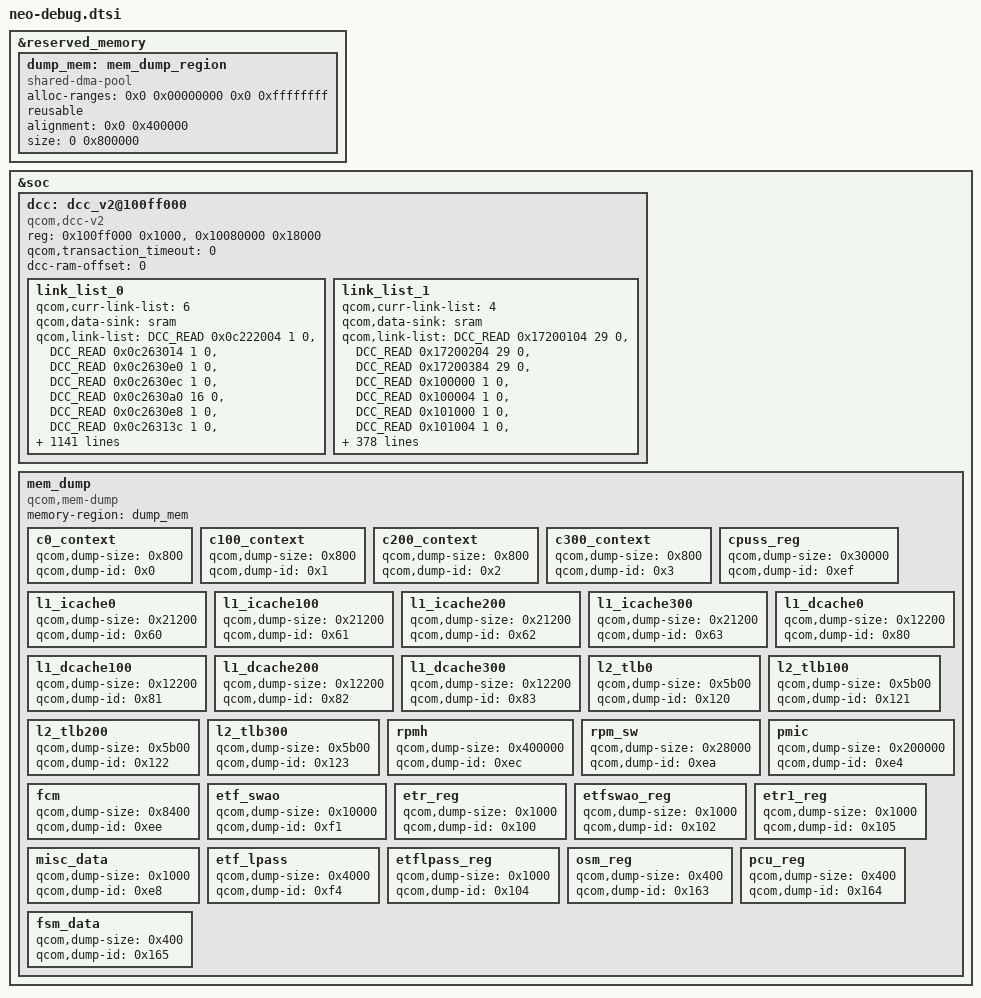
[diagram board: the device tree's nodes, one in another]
#include <dt-bindings/soc/qcom,dcc_v2.h>

&reserved_memory {
	#address-cells = <2>;
	#size-cells = <2>;
	ranges;

	dump_mem: mem_dump_region {
		compatible = "shared-dma-pool";
		alloc-ranges = <0x0 0x00000000 0x0 0xffffffff>;
		reusable;
		alignment = <0x0 0x400000>;
		size = <0 0x800000>;
	};
};

&soc {

	dcc: dcc_v2@100ff000 {
		compatible = "qcom,dcc-v2";
		reg = <0x100ff000 0x1000>,
		      <0x10080000 0x18000>;

		qcom,transaction_timeout = <0>;

		reg-names = "dcc-base", "dcc-ram-base";
		dcc-ram-offset = <0>;

		link_list_0 {
			qcom,curr-link-list = <6>;
			qcom,data-sink = "sram";
			qcom,link-list = <DCC_READ 0x0c222004 1 0>,
					<DCC_READ 0x0c263014 1 0>,
					<DCC_READ 0x0c2630e0 1 0>,
					<DCC_READ 0x0c2630ec 1 0>,
					<DCC_READ 0x0c2630a0 16 0>,
					<DCC_READ 0x0c2630e8 1 0>,
					<DCC_READ 0x0c26313c 1 0>,
					<DCC_READ 0x17b784a0 12 0>,
					<DCC_READ 0x17b78520 1 0>,
					<DCC_READ 0x17b78588 1 0>,
					<DCC_READ 0x17b78D90 8 0>,
					<DCC_READ 0x17b79010 6 0>,
					<DCC_READ 0x17b79090 6 0>,
					<DCC_READ 0x17b79a90 4 0>,
					<DCC_READ 0xec80010 1 0>,
					<DCC_READ 0xec81000 1 0>,
					<DCC_READ 0xec81010 16 0>,
					<DCC_READ 0xec81050 16 0>,
					<DCC_READ 0xec81090 16 0>,
					<DCC_READ 0xec810d0 16 0>,
					<DCC_READ 0x17800058 1 0>,
					<DCC_READ 0x17810058 1 0>,
					<DCC_READ 0x17820058 1 0>,
					<DCC_READ 0x17830058 1 0>,
					<DCC_READ 0x1780005c 1 0>,
					<DCC_READ 0x1781005c 1 0>,
					<DCC_READ 0x1782005c 1 0>,
					<DCC_READ 0x1783005c 1 0>,
					<DCC_READ 0x1740003c 1 0>,
					<DCC_READ 0x17800060 1 0>,
					<DCC_READ 0x17810060 1 0>,
					<DCC_READ 0x17820060 1 0>,
					<DCC_READ 0x17830060 1 0>,
					<DCC_READ 0x17800064 1 0>,
					<DCC_READ 0x17810064 1 0>,
					<DCC_READ 0x17820064 1 0>,
					<DCC_READ 0x17830064 1 0>,
					<DCC_READ 0x17600238 1 0>,
					<DCC_READ 0x17600404 3 0>,
					<DCC_READ 0x1760041c 3 0>,
					<DCC_READ 0x17600434 1 0>,
					<DCC_READ 0x1760043c 1 0>,
					<DCC_READ 0x17600440 1 0>,
					<DCC_READ 0x17800010 1 0>,
					<DCC_READ 0x17800024 1 0>,
					<DCC_READ 0x17800038 1 0>,
					<DCC_READ 0x1780003c 1 0>,
					<DCC_READ 0x17800040 1 0>,
					<DCC_READ 0x17800044 1 0>,
					<DCC_READ 0x17800048 1 0>,
					<DCC_READ 0x1780004c 1 0>,
					<DCC_READ 0x1780006c 1 0>,
					<DCC_READ 0x178000f0 1 0>,
					<DCC_READ 0x178000f4 1 0>,
					<DCC_READ 0x17810010 1 0>,
					<DCC_READ 0x17810024 1 0>,
					<DCC_READ 0x17810038 1 0>,
					<DCC_READ 0x1781003c 1 0>,
					<DCC_READ 0x17810040 1 0>,
					<DCC_READ 0x17810044 1 0>,
					<DCC_READ 0x17810048 1 0>,
					<DCC_READ 0x1781004c 1 0>,
					<DCC_READ 0x1781006c 1 0>,
					<DCC_READ 0x178100f0 1 0>,
					<DCC_READ 0x178100f4 1 0>,
					<DCC_READ 0x17820010 1 0>,
					<DCC_READ 0x17820024 1 0>,
					<DCC_READ 0x17820038 1 0>,
					<DCC_READ 0x1782003c 1 0>,
					<DCC_READ 0x17820040 1 0>,
					<DCC_READ 0x17820044 1 0>,
					<DCC_READ 0x17820048 1 0>,
					<DCC_READ 0x1782004c 1 0>,
					<DCC_READ 0x1782006c 1 0>,
					<DCC_READ 0x178200f0 1 0>,
					<DCC_READ 0x178200f4 1 0>,
					<DCC_READ 0x17830010 1 0>,
					<DCC_READ 0x17830024 1 0>,
					<DCC_READ 0x17830038 1 0>,
					<DCC_READ 0x1783003c 1 0>,
					<DCC_READ 0x17830040 1 0>,
					<DCC_READ 0x17830044 1 0>,
					<DCC_READ 0x17830048 1 0>,
					<DCC_READ 0x1783004c 1 0>,
					<DCC_READ 0x1783006c 1 0>,
					<DCC_READ 0x178300f0 1 0>,
					<DCC_READ 0x178300f4 1 0>,
					<DCC_READ 0x17880010 1 0>,
					<DCC_READ 0x17880024 1 0>,
					<DCC_READ 0x17880038 1 0>,
					<DCC_READ 0x1788003c 1 0>,
					<DCC_READ 0x17880040 1 0>,
					<DCC_READ 0x17880044 1 0>,
					<DCC_READ 0x17880048 1 0>,
					<DCC_READ 0x1788004c 1 0>,
					<DCC_READ 0x1788006c 1 0>,
					<DCC_READ 0x17880070 1 0>,
					<DCC_READ 0x17880074 1 0>,
					<DCC_READ 0x17880078 1 0>,
					<DCC_READ 0x1788007c 1 0>,
					<DCC_READ 0x17880084 1 0>,
					<DCC_READ 0x178800f4 1 0>,
					<DCC_READ 0x178800f8 1 0>,
					<DCC_READ 0x178800fc 1 0>,
					<DCC_READ 0x17880100 1 0>,
					<DCC_READ 0x17880104 1 0>,
					<DCC_READ 0x17880134 1 0>,
					<DCC_READ 0x17880138 1 0>,
					<DCC_READ 0x178801b4 1 0>,
					<DCC_READ 0x178801bc 1 0>,
					<DCC_READ 0x178801c0 1 0>,
					<DCC_READ 0x178801c8 1 0>,
					<DCC_READ 0xb281024 1 0>,
					<DCC_READ 0xbde1034 1 0>,
					<DCC_READ 0xb201020 2 0>,
					<DCC_READ 0xb211020 2 0>,
					<DCC_READ 0xb221020 2 0>,
					<DCC_READ 0xb231020 2 0>,
					<DCC_READ 0xb204520 1 0>,
					<DCC_READ 0x0b200010 4 0>,
					<DCC_READ 0x0b200900 4 0>,
					<DCC_READ 0x0b201030 1 0>,
					<DCC_READ 0x0b201204 2 0>,
					<DCC_READ 0x0b201218 2 0>,
					<DCC_READ 0x0b20122c 2 0>,
					<DCC_READ 0x0b201240 2 0>,
					<DCC_READ 0x0b201254 2 0>,
					<DCC_READ 0x0b204510 2 0>,
					<DCC_READ 0x0b220010 4 0>,
					<DCC_READ 0x0b220900 4 0>,
					<DCC_READ 0x17a00010 1 0>,
					<DCC_READ 0x17a10010 1 0>,
					<DCC_READ 0x17a20010 1 0>,
					<DCC_READ 0x17a30010 1 0>,
					<DCC_READ 0x17a00030 1 0>,
					<DCC_READ 0x17a10030 1 0>,
					<DCC_READ 0x17a20030 1 0>,
					<DCC_READ 0x17a30030 1 0>,
					<DCC_READ 0x17a00038 1 0>,
					<DCC_READ 0x17a10038 1 0>,
					<DCC_READ 0x17a20038 1 0>,
					<DCC_READ 0x17a30038 1 0>,
					<DCC_READ 0x17a00040 1 0>,
					<DCC_READ 0x17a10040 1 0>,
					<DCC_READ 0x17a20040 1 0>,
					<DCC_READ 0x17a30040 1 0>,
					<DCC_READ 0x17a00048 1 0>,
					<DCC_READ 0x17a00400 3 0>,
					<DCC_READ 0x17a10400 3 0>,
					<DCC_READ 0x17a20400 3 0>,
					<DCC_READ 0x17a30400 3 0>,
					<DCC_READ 0x17D80100 144 0>,
					<DCC_READ 0x17d9001c 1 0>,
					<DCC_READ 0x17d900dc 1 0>,
					<DCC_READ 0x17d900e8 1 0>,
					<DCC_READ 0x17d90320 1 0>,
					<DCC_READ 0x17d90020 1 0>,
					<DCC_READ 0x17D9034C 1 0>,
					<DCC_READ 0x17D90300 1 0>,
					<DCC_READ 0x17d9101c 1 0>,
					<DCC_READ 0x17d910dc 1 0>,
					<DCC_READ 0x17d910e8 1 0>,
					<DCC_READ 0x17d91320 1 0>,
					<DCC_READ 0x17d91020 1 0>,
					<DCC_READ 0x17D9134C 1 0>,
					<DCC_READ 0x17D91300 1 0>,
					<DCC_READ 0x12822000 1 0>,
					<DCC_READ 0x12822004 1 0>,
					<DCC_READ 0x12824C00 1 0>,
					<DCC_READ 0x12824D04 1 0>,
					<DCC_READ 0x12824D08 1 0>,
					<DCC_READ 0x17D98014 1 0>,
					<DCC_READ 0x17D98018 1 0>,
					<DCC_READ 0x17D9801C 1 0>,
					<DCC_READ 0x17D98020 1 0>,
					<DCC_READ 0x17D900E0 1 0>,
					<DCC_READ 0x17D90410 1 0>,
					<DCC_READ 0x17D90074 1 0>,
					<DCC_READ 0x17D90064 1 0>,
					<DCC_READ 0x17D91074 1 0>,
					<DCC_READ 0x17D910E0 1 0>,
					<DCC_READ 0x17D91410 1 0>,
					<DCC_READ 0x17d80100 0x90 0>,
					<DCC_READ 0x17d9034c 1 0>,
					<DCC_READ 0x17d9134c 1 0>,
					<DCC_READ 0x17400038 1 0>,
					<DCC_READ 0x17d98010 1 0>,
					<DCC_READ 0x01fc8000 1 0>,
					<DCC_READ 0x610110 5 0>,
					<DCC_READ 0x1908e008 1 0>,
					<DCC_READ 0x190ba280 1 0>,
					<DCC_READ 0x192e0610 1 0>,
					<DCC_READ 0x190ba288 8 0>,
					<DCC_READ 0x192e0614 3 0>,
					<DCC_READ 0x19a00000 2 0>,
					<DCC_READ 0x19238100 1 0>,
					<DCC_READ 0x192420b0 1 0>,
					<DCC_READ 0x19242044 4 0>,
					<DCC_READ 0x1924c180 18 0>,
					<DCC_READ 0x1924c1c8 1 0>,
					<DCC_READ 0x19250020 1 0>,
					<DCC_READ 0x192521b0 16 0>,
					<DCC_READ 0x1926005c 5 0>,
					<DCC_READ 0x192c0410 3 0>,
					<DCC_READ 0x192c0420 2 0>,
					<DCC_READ 0x192c0430 1 0>,
					<DCC_READ 0x192c0440 1 0>,
					<DCC_READ 0x192c0448 1 0>,
					<DCC_READ 0x192c04a0 1 0>,
					<DCC_READ 0x192c04b0 1 0>,
					<DCC_READ 0x19338100 1 0>,
					<DCC_READ 0x193420b0 1 0>,
					<DCC_READ 0x19342044 4 0>,
					<DCC_READ 0x1934c180 1 0>,
					<DCC_READ 0x1934c1c8 1 0>,
					<DCC_READ 0x19350020 1 0>,
					<DCC_READ 0x193521b0 1 0>,
					<DCC_READ 0x1936005c 5 0>,
					<DCC_READ 0x19a00000 1 0>,
					<DCC_READ 0x19a00004 1 0>,
					<DCC_READ 0x19a01000 1 0>,
					<DCC_READ 0x19a01004 1 0>,
					<DCC_READ 0x19a02000 1 0>,
					<DCC_READ 0x19a02004 1 0>,
					<DCC_READ 0x19a03000 1 0>,
					<DCC_READ 0x19a03004 1 0>,
					<DCC_READ 0x19a04000 1 0>,
					<DCC_READ 0x19a04004 1 0>,
					<DCC_READ 0x19a05000 1 0>,
					<DCC_READ 0x19a05004 1 0>,
					<DCC_READ 0x19a06000 1 0>,
					<DCC_READ 0x19a06004 1 0>,
					<DCC_READ 0x19a07000 1 0>,
					<DCC_READ 0x19a07004 1 0>,
					<DCC_READ 0x19a08000 1 0>,
					<DCC_READ 0x19a08004 1 0>,
					<DCC_READ 0x19a09000 1 0>,
					<DCC_READ 0x19a09004 1 0>,
					<DCC_READ 0x19a0a000 1 0>,
					<DCC_READ 0x19a0a004 1 0>,
					<DCC_READ 0x19a0b000 1 0>,
					<DCC_READ 0x19a0b004 1 0>,
					<DCC_READ 0x19a0c000 1 0>,
					<DCC_READ 0x19a0c004 1 0>,
					<DCC_READ 0x19a0d000 1 0>,
					<DCC_READ 0x19a0d004 1 0>,
					<DCC_READ 0x19a0e000 1 0>,
					<DCC_READ 0x19a0e004 1 0>,
					<DCC_READ 0x19a0f000 1 0>,
					<DCC_READ 0x19a0f004 1 0>,
					<DCC_READ 0x19a10000 1 0>,
					<DCC_READ 0x19a10004 1 0>,
					<DCC_READ 0x19a11000 1 0>,
					<DCC_READ 0x19a11004 1 0>,
					<DCC_READ 0x19a12000 1 0>,
					<DCC_READ 0x19a12004 1 0>,
					<DCC_READ 0x19a13000 1 0>,
					<DCC_READ 0x19a13004 1 0>,
					<DCC_READ 0x19a14000 1 0>,
					<DCC_READ 0x19a14004 1 0>,
					<DCC_READ 0x19a15000 1 0>,
					<DCC_READ 0x19a15004 1 0>,
					<DCC_READ 0x19a16000 1 0>,
					<DCC_READ 0x19a16004 1 0>,
					<DCC_READ 0x19a17000 1 0>,
					<DCC_READ 0x19a17004 1 0>,
					<DCC_READ 0x19a18000 1 0>,
					<DCC_READ 0x19a18004 1 0>,
					<DCC_READ 0x19a19000 1 0>,
					<DCC_READ 0x19a19004 1 0>,
					<DCC_READ 0x19a1a000 1 0>,
					<DCC_READ 0x19a1a004 1 0>,
					<DCC_READ 0x19a1b000 1 0>,
					<DCC_READ 0x19a1b004 1 0>,
					<DCC_READ 0x19a1c000 1 0>,
					<DCC_READ 0x19a1c004 1 0>,
					<DCC_READ 0x19a1d000 1 0>,
					<DCC_READ 0x19a1d004 1 0>,
					<DCC_READ 0x19a1e000 1 0>,
					<DCC_READ 0x19a1e004 1 0>,
					<DCC_READ 0x19a1f000 1 0>,
					<DCC_READ 0x19a1f004 1 0>,
					<DCC_READ 0x192c6418 1 0>,
					<DCC_READ 0x192c5804 1 0>,
					<DCC_READ 0x192c04b8 1 0>,
					<DCC_READ 0x192856d4 4 0>,
					<DCC_READ 0x19281b1c 3 0>,
					<DCC_READ 0x19283b1c 3 0>,
					<DCC_READ 0x19285188 3 0>,
					<DCC_READ 0x19281db4 1 0>,
					<DCC_READ 0x19281dbc 1 0>,
					<DCC_READ 0x19281dc4 1 0>,
					<DCC_READ 0x19283db4 1 0>,
					<DCC_READ 0x19283dbc 1 0>,
					<DCC_READ 0x19283dc4 1 0>,
					<DCC_READ 0x1928583c 1 0>,
					<DCC_READ 0x1928581c 1 0>,
					<DCC_READ 0x192857fc 1 0>,
					<DCC_READ 0x19285830 1 0>,
					<DCC_READ 0x19285840 1 0>,
					<DCC_READ 0x19285848 1 0>,
					<DCC_READ 0x19285810 1 0>,
					<DCC_READ 0x19285258 1 0>,
					<DCC_READ 0x19281f20 2 0>,
					<DCC_READ 0x19281e6c 1 0>,
					<DCC_READ 0x19283e6c 1 0>,
					<DCC_READ 0x192c5240 2 0>,
					<DCC_READ 0x192c5b1c 1 0>,
					<DCC_READ 0x192c5b20 1 0>,
					<DCC_READ 0x192c5b24 1 0>,
					<DCC_READ 0x19032020 1 0>,
					<DCC_READ 0x19032024 1 0>,
					<DCC_READ 0x1908E01C 1 0>,
					<DCC_READ 0x1908E030 1 0>,
					<DCC_READ 0x19030010 1 0>,
					<DCC_READ 0x1908e008 1 0>,
					<DCC_READ 0x19032020 1 0>,
					<DCC_READ 0x1908e948 1 0>,
					<DCC_READ 0x19032024 1 0>,
					<DCC_WRITE 0x19030040 0x1 0>,
					<DCC_WRITE 0x1903005C 0x22C000 0>,
					<DCC_READ 0x19030010 1 0>,
					<DCC_WRITE 0x1903005C 0x22C001 0>,
					<DCC_READ 0x19030010 1 0>,
					<DCC_WRITE 0x1903005C 0x22C002 0>,
					<DCC_READ 0x19030010 1 0>,
					<DCC_WRITE 0x1903005C 0x22C003 0>,
					<DCC_READ 0x19030010 1 0>,
					<DCC_WRITE 0x1903005C 0x22C004 0>,
					<DCC_READ 0x19030010 1 0>,
					<DCC_WRITE 0x1903005C 0x22C005 0>,
					<DCC_READ 0x19030010 1 0>,
					<DCC_WRITE 0x1903005C 0x22C006 0>,
					<DCC_READ 0x19030010 1 0>,
					<DCC_WRITE 0x1903005C 0x22C007 0>,
					<DCC_READ 0x19030010 1 0>,
					<DCC_WRITE 0x1903005C 0x22C008 0>,
					<DCC_READ 0x19030010 1 0>,
					<DCC_WRITE 0x1903005C 0x22C009 0>,
					<DCC_READ 0x19030010 1 0>,
					<DCC_WRITE 0x1903005C 0x22C00A 0>,
					<DCC_READ 0x19030010 1 0>,
					<DCC_WRITE 0x1903005C 0x22C00B 0>,
					<DCC_READ 0x19030010 1 0>,
					<DCC_WRITE 0x1903005C 0x22C00C 0>,
					<DCC_READ 0x19030010 1 0>,
					<DCC_WRITE 0x1903005C 0x22C00D 0>,
					<DCC_READ 0x19030010 1 0>,
					<DCC_WRITE 0x1903005C 0x22C00E 0>,
					<DCC_READ 0x19030010 1 0>,
					<DCC_WRITE 0x1903005C 0x22C00F 0>,
					<DCC_READ 0x19030010 1 0>,
					<DCC_WRITE 0x1903005C 0x22C010 0>,
					<DCC_READ 0x19030010 1 0>,
					<DCC_WRITE 0x1903005C 0x22C011 0>,
					<DCC_READ 0x19030010 1 0>,
					<DCC_WRITE 0x1903005C 0x22C012 0>,
					<DCC_READ 0x19030010 1 0>,
					<DCC_WRITE 0x1903005C 0x22C013 0>,
					<DCC_READ 0x19030010 1 0>,
					<DCC_WRITE 0x1903005C 0x22C014 0>,
					<DCC_READ 0x19030010 1 0>,
					<DCC_WRITE 0x1903005C 0x22C015 0>,
					<DCC_READ 0x19030010 1 0>,
					<DCC_WRITE 0x1903005C 0x22C016 0>,
					<DCC_READ 0x19030010 1 0>,
					<DCC_WRITE 0x1903005C 0x22C017 0>,
					<DCC_READ 0x19030010 1 0>,
					<DCC_WRITE 0x1903005C 0x22C018 0>,
					<DCC_READ 0x19030010 1 0>,
					<DCC_WRITE 0x1903005C 0x22C019 0>,
					<DCC_READ 0x19030010 1 0>,
					<DCC_WRITE 0x1903005C 0x22C01A 0>,
					<DCC_READ 0x19030010 1 0>,
					<DCC_WRITE 0x1903005C 0x22C01B 0>,
					<DCC_READ 0x19030010 1 0>,
					<DCC_WRITE 0x1903005C 0x22C01C 0>,
					<DCC_READ 0x19030010 1 0>,
					<DCC_WRITE 0x1903005C 0x22C01D 0>,
					<DCC_READ 0x19030010 1 0>,
					<DCC_WRITE 0x1903005C 0x22C01E 0>,
					<DCC_READ 0x19030010 1 0>,
					<DCC_WRITE 0x1903005C 0x22C01F 0>,
					<DCC_READ 0x19030010 1 0>,
					<DCC_WRITE 0x1903005C 0x22C300 0>,
					<DCC_READ 0x19030010 1 0>,
					<DCC_WRITE 0x1903005C 0x22C341 0>,
					<DCC_READ 0x19030010 1 0>,
					<DCC_WRITE 0x1903005C 0x22C7B1 0>,
					<DCC_READ 0x19030010 1 0>,
					<DCC_READ 0x129000 1 0>,
					<DCC_READ 0x12903c 1 0>,
					<DCC_READ 0x19b004 1 0>,
					<DCC_READ 0x19b00c 1 0>,
					<DCC_READ 0x19b010 1 0>,
					<DCC_READ 0x19b014 1 0>,
					<DCC_READ 0x19b018 1 0>,
					<DCC_READ 0x181154 1 0>,
					<DCC_READ 0x18b000 1 0>,
					<DCC_READ 0x18b03c 1 0>,
					<DCC_READ 0x18c000 1 0>,
					<DCC_READ 0x18c03c 1 0>,
					<DCC_READ 0x18d000 1 0>,
					<DCC_READ 0x18d03c 1 0>,
					<DCC_READ 0x18e000 1 0>,
					<DCC_READ 0x18e03c 1 0>,
					<DCC_READ 0x3d99004 1 0>,
					<DCC_READ 0x3d9905c 1 0>,
					<DCC_READ 0x3d99060 1 0>,
					<DCC_READ 0x3d99064 1 0>,
					<DCC_READ 0x3d990a8 1 0>,
					<DCC_READ 0x3d990b0 1 0>,
					<DCC_READ 0x3d990b4 1 0>,
					<DCC_READ 0x3d990b8 1 0>,
					<DCC_READ 0x3d990bc 1 0>,
					<DCC_READ 0x3d99108 1 0>,
					<DCC_READ 0x3d9910c 1 0>,
					<DCC_READ 0x3d99110 1 0>,
					<DCC_READ 0x3d9911c 1 0>,
					<DCC_READ 0x3d99120 1 0>,
					<DCC_READ 0x3d99124 1 0>,
					<DCC_READ 0x3d99128 1 0>,
					<DCC_READ 0x3d9912c 1 0>,
					<DCC_READ 0x3d99134 1 0>,
					<DCC_READ 0x3d99138 1 0>,
					<DCC_READ 0x3d9913c 1 0>,
					<DCC_READ 0x3d99144 1 0>,
					<DCC_READ 0x3d9919c 1 0>,
					<DCC_READ 0x3d991a0 1 0>,
					<DCC_READ 0x3d99224 1 0>,
					<DCC_READ 0x3d99228 1 0>,
					<DCC_READ 0x3d99274 1 0>,
					<DCC_READ 0x3d99284 1 0>,
					<DCC_READ 0x3d9935c 1 0>,
					<DCC_READ 0x3d99360 1 0>,
					<DCC_READ 0x3d993a4 1 0>,
					<DCC_READ 0x3d993e8 1 0>,
					<DCC_READ 0x3d99148 1 0>,
					<DCC_READ 0x3d99008 1 0>,
					<DCC_READ 0x3d96000 1 0>,
					<DCC_READ 0x3d96004 1 0>,
					<DCC_READ 0x3d95000 1 0>,
					<DCC_READ 0x3d95004 1 0>,
					<DCC_READ 0x3d97000 1 0>,
					<DCC_READ 0x3d97004 1 0>,
					<DCC_READ 0x3d99278 1 0>,
					<DCC_READ 0x3d99288 1 0>,
					<DCC_READ 0x3d9928c 1 0>,
					<DCC_READ 0x3d99530 1 0>,
					<DCC_READ 0x3d002b4 1 0>,
					<DCC_READ 0x3d00410 1 0>,
					<DCC_READ 0x3d00414 1 0>,
					<DCC_READ 0x3d00818 1 0>,
					<DCC_READ 0x3d00800 1 0>,
					<DCC_READ 0x3d00840 1 0>,
					<DCC_READ 0x3d00804 1 0>,
					<DCC_READ 0x3d000e0 1 0>,
					<DCC_READ 0x3d8ec30 1 0>,
					<DCC_READ 0x3d7e340 1 0>,
					<DCC_READ 0x3d3c000 1 0>,
					<DCC_READ 0x3d3c004 1 0>,
					<DCC_READ 0x3DA2300 1 0>,
					<DCC_READ 0xAF09000 1 0>,
					<DCC_READ 0x17900908 1 0>,
					<DCC_READ 0x17900c18 1 0>,
					<DCC_WRITE 0x17A80000 0x8007 0>,
					<DCC_READ 0x17A80000 1 0>,
					<DCC_WRITE 0x17A80028 0x0 0>,
					<DCC_READ 0x17A80028 1 0>,
					<DCC_WRITE 0x17A80024 0x0 0>,
					<DCC_READ 0x17A80024 1 0>,
					<DCC_READ 0x17A8003C 1 0>,
					<DCC_WRITE 0x17A80024 0x40 0>,
					<DCC_READ 0x17A80024 1 0>,
					<DCC_READ 0x17A8003C 1 0>,
					<DCC_WRITE 0x17A80024 0x80 0>,
					<DCC_READ 0x17A80024 1 0>,
					<DCC_READ 0x17A8003C 1 0>,
					<DCC_WRITE 0x17A80024 0xc0 0>,
					<DCC_READ 0x17A80024 1 0>,
					<DCC_READ 0x17A8003C 1 0>,
					<DCC_WRITE 0x17A80024 0x100 0>,
					<DCC_READ 0x17A80024 1 0>,
					<DCC_READ 0x17A8003C 1 0>,
					<DCC_WRITE 0x17A80024 0x140 0>,
					<DCC_READ 0x17A80024 1 0>,
					<DCC_READ 0x17A8003C 1 0>,
					<DCC_WRITE 0x17A80024 0x180 0>,
					<DCC_READ 0x17A80024 1 0>,
					<DCC_READ 0x17A8003C 1 0>,
					<DCC_WRITE 0x17A80024 0x1c0 0>,
					<DCC_READ 0x17A80024 1 0>,
					<DCC_READ 0x17A8003C 1 0>,
					<DCC_WRITE 0x17A80024 0x200 0>,
					<DCC_READ 0x17A80024 1 0>,
					<DCC_READ 0x17A8003C 1 0>,
					<DCC_WRITE 0x17A80024 0x240 0>,
					<DCC_READ 0x17A80024 1 0>,
					<DCC_READ 0x17A8003C 1 0>,
					<DCC_WRITE 0x17A80024 0x280 0>,
					<DCC_READ 0x17A80024 1 0>,
					<DCC_READ 0x17A8003C 1 0>,
					<DCC_WRITE 0x17A80024 0x2c0 0>,
					<DCC_READ 0x17A80024 1 0>,
					<DCC_READ 0x17A8003C 1 0>,
					<DCC_WRITE 0x17A80024 0x300 0>,
					<DCC_READ 0x17A80024 1 0>,
					<DCC_READ 0x17A8003C 1 0>,
					<DCC_WRITE 0x17A80024 0x340 0>,
					<DCC_READ 0x17A80024 1 0>,
					<DCC_READ 0x17A8003C 1 0>,
					<DCC_WRITE 0x17A80024 0x380 0>,
					<DCC_READ 0x17A80024 1 0>,
					<DCC_READ 0x17A8003C 1 0>,
					<DCC_WRITE 0x17A80024 0x3c0 0>,
					<DCC_READ 0x17A80024 1 0>,
					<DCC_READ 0x17A8003C 1 0>,
					<DCC_WRITE 0x17a80024 0x4000 0>,
					<DCC_READ 0x17a80024 1 0>,
					<DCC_WRITE 0x17A80024 0x0 0>,
					<DCC_READ 0x17A80024 1 0>,
					<DCC_WRITE 0x17A80024 0x0 0>,
					<DCC_READ 0x17A80024 1 0>,
					<DCC_WRITE 0x17A80024 0x0 0>,
					<DCC_READ 0x17A80024 1 0>,
					<DCC_READ 0x17A8003C 1 0>,
					<DCC_WRITE 0x17A80024 0x40 0>,
					<DCC_READ 0x17A80024 1 0>,
					<DCC_READ 0x17A8003C 1 0>,
					<DCC_WRITE 0x17a84000 0x8007 0>,
					<DCC_READ 0x17a84000 1 0>,
					<DCC_WRITE 0x17a84024 0x0 0>,
					<DCC_READ 0x17a84024 1 0>,
					<DCC_WRITE 0x17a84020 0x0 0>,
					<DCC_READ 0x17a84020 1 0>,
					<DCC_READ 0x17A8400C 1 0>,
					<DCC_WRITE 0x17a84020 0x40 0>,
					<DCC_READ 0x17a84020 1 0>,
					<DCC_READ 0x17A8400C 1 0>,
					<DCC_WRITE 0x17a84020 0x80 0>,
					<DCC_READ 0x17a84020 1 0>,
					<DCC_READ 0x17A8400C 1 0>,
					<DCC_WRITE 0x17a84020 0xc0 0>,
					<DCC_READ 0x17a84020 1 0>,
					<DCC_READ 0x17A8400C 1 0>,
					<DCC_WRITE 0x17a84020 0x100 0>,
					<DCC_READ 0x17a84020 1 0>,
					<DCC_READ 0x17A8400C 1 0>,
					<DCC_WRITE 0x17a84020 0x140 0>,
					<DCC_READ 0x17a84020 1 0>,
					<DCC_READ 0x17A8400C 1 0>,
					<DCC_WRITE 0x17a84020 0x180 0>,
					<DCC_READ 0x17a84020 1 0>,
					<DCC_READ 0x17A8400C 1 0>,
					<DCC_WRITE 0x17a84020 0x1c0 0>,
					<DCC_READ 0x17a84020 1 0>,
					<DCC_READ 0x17A8400C 1 0>,
					<DCC_WRITE 0x17a84020 0x200 0>,
					<DCC_READ 0x17a84020 1 0>,
					<DCC_READ 0x17A8400C 1 0>,
					<DCC_WRITE 0x17a84020 0x240 0>,
					<DCC_READ 0x17a84020 1 0>,
					<DCC_READ 0x17A8400C 1 0>,
					<DCC_WRITE 0x17a84020 0x280 0>,
					<DCC_READ 0x17a84020 1 0>,
					<DCC_READ 0x17A8400C 1 0>,
					<DCC_WRITE 0x17a84020 0x2c0 0>,
					<DCC_READ 0x17a84020 1 0>,
					<DCC_READ 0x17A8400C 1 0>,
					<DCC_WRITE 0x17a84020 0x300 0>,
					<DCC_READ 0x17a84020 1 0>,
					<DCC_READ 0x17A8400C 1 0>,
					<DCC_WRITE 0x17a84020 0x340 0>,
					<DCC_READ 0x17a84020 1 0>,
					<DCC_READ 0x17A8400C 1 0>,
					<DCC_WRITE 0x17a84020 0x380 0>,
					<DCC_READ 0x17a84020 1 0>,
					<DCC_READ 0x17A8400C 1 0>,
					<DCC_WRITE 0x17a84020 0x3c0 0>,
					<DCC_READ 0x17a84020 1 0>,
					<DCC_READ 0x17A8400C 1 0>,
					<DCC_WRITE 0x17a84024 0x4000 0>,
					<DCC_READ 0x17a84024 1 0>,
					<DCC_WRITE 0x17a84020 0x0 0>,
					<DCC_READ 0x17a84020 1 0>,
					<DCC_WRITE 0x17a84020 0x0 0>,
					<DCC_READ 0x17a84020 1 0>,
					<DCC_WRITE 0x17a84020 0x0 0>,
					<DCC_READ 0x17a84020 1 0>,
					<DCC_READ 0x17A8400C 1 0>,
					<DCC_WRITE 0x17a84020 0x40 0>,
					<DCC_READ 0x17a84020 1 0>,
					<DCC_READ 0x17A8400C 1 0>,
					<DCC_READ 0x17a94030 1 0>,
					<DCC_READ 0x17a9408c 1 0>,
					<DCC_WRITE 0x17a9409c 0x78 0>,
					<DCC_WRITE 0x17a9409c 0x0 0>,
					<DCC_WRITE 0x17a94048 0x1 0>,
					<DCC_WRITE 0x17a94090 0x0 0>,
					<DCC_WRITE 0x17a94090 0x25 0>,
					<DCC_READ 0x17a94098 1 0>,
					<DCC_WRITE 0x17a94048 0x1D 0>,
					<DCC_WRITE 0x17a94090 0x0 0>,
					<DCC_WRITE 0x17a94090 0x25 0>,
					<DCC_READ 0x17a94098 1 0>,
					<DCC_READ 0x17a90030 1 0>,
					<DCC_READ 0x17a9008c 1 0>,
					<DCC_WRITE 0x17a9009c 0x78 0>,
					<DCC_WRITE 0x17a9009c 0x0 0>,
					<DCC_WRITE 0x17a90048 0x1 0>,
					<DCC_WRITE 0x17a90090 0x0 0>,
					<DCC_WRITE 0x17a90090 0x25 0>,
					<DCC_READ 0x17a90098 1 0>,
					<DCC_WRITE 0x17a90048 0x1D 0>,
					<DCC_WRITE 0x17a90090 0x0 0>,
					<DCC_WRITE 0x17a90090 0x25 0>,
					<DCC_READ 0x17a90098 1 0>,
					<DCC_READ 0x17ba0000 6 0>,
					<DCC_READ 0x17ba0020 5 0>,
					<DCC_READ 0x17ba0050 1 0>,
					<DCC_READ 0x17ba0070 1 0>,
					<DCC_READ 0x17ba0080 25 0>,
					<DCC_READ 0x17ba0100 1 0>,
					<DCC_READ 0x17ba0120 1 0>,
					<DCC_READ 0x17ba0140 1 0>,
					<DCC_READ 0x17ba0200 6 0>,
					<DCC_READ 0x17ba0700 1 0>,
					<DCC_READ 0x17ba070c 3 0>,
					<DCC_READ 0x17ba0780 32 0>,
					<DCC_READ 0x17ba0808 1 0>,
					<DCC_READ 0x17ba0c48 1 0>,
					<DCC_READ 0x17ba080c 1 0>,
					<DCC_READ 0x17ba0c4c 1 0>,
					<DCC_READ 0x17ba0810 1 0>,
					<DCC_READ 0x17ba0c50 1 0>,
					<DCC_READ 0x17ba0814 1 0>,
					<DCC_READ 0x17ba0c54 1 0>,
					<DCC_READ 0x17ba0818 1 0>,
					<DCC_READ 0x17ba0c58 1 0>,
					<DCC_READ 0x17ba081c 1 0>,
					<DCC_READ 0x17ba0c5c 1 0>,
					<DCC_READ 0x17ba0824 1 0>,
					<DCC_READ 0x17ba0c64 1 0>,
					<DCC_READ 0x17ba0828 1 0>,
					<DCC_READ 0x17ba0c68 1 0>,
					<DCC_READ 0x17ba082c 1 0>,
					<DCC_READ 0x17ba0c6c 1 0>,
					<DCC_READ 0x17ba0840 1 0>,
					<DCC_READ 0x17ba0c80 1 0>,
					<DCC_READ 0x17ba0844 1 0>,
					<DCC_READ 0x17ba0c84 1 0>,
					<DCC_READ 0x17ba0848 1 0>,
					<DCC_READ 0x17ba0c88 1 0>,
					<DCC_READ 0x17ba084c 1 0>,
					<DCC_READ 0x17ba0c8c 1 0>,
					<DCC_READ 0x17ba0850 1 0>,
					<DCC_READ 0x17ba0c90 1 0>,
					<DCC_READ 0x17ba0854 1 0>,
					<DCC_READ 0x17ba0c94 1 0>,
					<DCC_READ 0x17ba0858 1 0>,
					<DCC_READ 0x17ba0c98 1 0>,
					<DCC_READ 0x17ba085c 1 0>,
					<DCC_READ 0x17ba0c9c 1 0>,
					<DCC_READ 0x17ba0860 1 0>,
					<DCC_READ 0x17ba0ca0 1 0>,
					<DCC_READ 0x17ba0864 1 0>,
					<DCC_READ 0x17ba0ca4 1 0>,
					<DCC_READ 0x17ba0868 1 0>,
					<DCC_READ 0x17ba0ca8 1 0>,
					<DCC_READ 0x17ba086c 1 0>,
					<DCC_READ 0x17ba0cac 1 0>,
					<DCC_READ 0x17ba0870 1 0>,
					<DCC_READ 0x17ba0cb0 1 0>,
					<DCC_READ 0x17ba0874 1 0>,
					<DCC_READ 0x17ba0cb4 1 0>,
					<DCC_READ 0x17ba0878 1 0>,
					<DCC_READ 0x17ba0cb8 1 0>,
					<DCC_READ 0x17ba087c 1 0>,
					<DCC_READ 0x17ba0cbc 1 0>,
					<DCC_READ 0x17ba3500 80 0>,
					<DCC_READ 0x17ba3a00 3 0>,
					<DCC_READ 0xc201244 1 0>,
					<DCC_READ 0xc202244 1 0>,
					<DCC_READ 0x17ba3b00 2 0>,
					<DCC_READ 0x17ba3b20 3 0>,
					<DCC_READ 0x17ba3b30 8 0>,
					<DCC_READ 0x17BA3B50 4 0>,
					<DCC_READ 0x17ba3b70 2 0>,
					<DCC_READ 0x17b00000 70 0>,
					<DCC_READ 0x19220344 9 0>,
					<DCC_READ 0x19220370 7 0>,
					<DCC_READ 0x19220480 1 0>,
					<DCC_READ 0x19222400 26 0>,
					<DCC_READ 0x19222470 5 0>,
					<DCC_READ 0x1922320c 1 0>,
					<DCC_READ 0x19223214 2 0>,
					<DCC_READ 0x19223220 4 0>,
					<DCC_READ 0x19223308 1 0>,
					<DCC_READ 0x19223318 1 0>,
					<DCC_READ 0x19223318 1 0>,
					<DCC_READ 0x1922358c 1 0>,
					<DCC_READ 0x19234010 1 0>,
					<DCC_READ 0x1923801c 8 0>,
					<DCC_READ 0x19238050 1 0>,
					<DCC_READ 0x19238100 1 0>,
					<DCC_READ 0x19238100 7 0>,
					<DCC_READ 0x1923c004 1 0>,
					<DCC_READ 0x1923c014 1 0>,
					<DCC_READ 0x1923c020 1 0>,
					<DCC_READ 0x1923c030 1 0>,
					<DCC_READ 0x1923c05c 3 0>,
					<DCC_READ 0x1923c074 1 0>,
					<DCC_READ 0x1923c088 1 0>,
					<DCC_READ 0x1923c0a0 1 0>,
					<DCC_READ 0x1923c0b0 1 0>,
					<DCC_READ 0x1923c0c0 1 0>,
					<DCC_READ 0x1923c0d0 1 0>,
					<DCC_READ 0x1923c0e0 1 0>,
					<DCC_READ 0x1923c0f0 1 0>,
					<DCC_READ 0x1923c100 1 0>,
					<DCC_READ 0x1923d064 1 0>,
					<DCC_READ 0x19240008 6 0>,
					<DCC_READ 0x19240028 1 0>,
					<DCC_READ 0x1924203c 3 0>,
					<DCC_READ 0x19242044 2 0>,
					<DCC_READ 0x19242048 2 0>,
					<DCC_READ 0x1924204c 10 0>,
					<DCC_READ 0x1924208c 1 0>,
					<DCC_READ 0x192420b0 1 0>,
					<DCC_READ 0x192420b0 1 0>,
					<DCC_READ 0x192420b8 3 0>,
					<DCC_READ 0x192420f4 1 0>,
					<DCC_READ 0x192420fc 3 0>,
					<DCC_READ 0x19242104 5 0>,
					<DCC_READ 0x19242114 1 0>,
					<DCC_READ 0x19242324 14 0>,
					<DCC_READ 0x19242410 1 0>,
					<DCC_READ 0x192430a8 1 0>,
					<DCC_READ 0x19248004 7 0>,
					<DCC_READ 0x19248024 1 0>,
					<DCC_READ 0x19248040 1 0>,
					<DCC_READ 0x19248048 1 0>,
					<DCC_READ 0x19249064 1 0>,
					<DCC_READ 0x1924c000 1 0>,
					<DCC_READ 0x1924c030 1 0>,
					<DCC_READ 0x1924c030 3 0>,
					<DCC_READ 0x1924c040 3 0>,
					<DCC_READ 0x1924c054 2 0>,
					<DCC_READ 0x1924c078 1 0>,
					<DCC_READ 0x1924c108 1 0>,
					<DCC_READ 0x1924c110 1 0>,
					<DCC_READ 0x19250020 1 0>,
					<DCC_READ 0x19250020 1 0>,
					<DCC_READ 0x19251054 1 0>,
					<DCC_READ 0x19252014 3 0>,
					<DCC_READ 0x19252028 1 0>,
					<DCC_READ 0x19252028 17 0>,
					<DCC_READ 0x19252070 8 0>,
					<DCC_READ 0x19252098 1 0>,
					<DCC_READ 0x192520a0 1 0>,
					<DCC_READ 0x192520b4 1 0>,
					<DCC_READ 0x192520c0 1 0>,
					<DCC_READ 0x192520d0 3 0>,
					<DCC_READ 0x192520f4 10 0>,
					<DCC_READ 0x19252120 12 0>,
					<DCC_READ 0x1925802c 1 0>,
					<DCC_READ 0x1925809c 2 0>,
					<DCC_READ 0x192580a8 3 0>,
					<DCC_READ 0x192580b8 1 0>,
					<DCC_READ 0x192580c0 7 0>,
					<DCC_READ 0x192580e0 1 0>,
					<DCC_READ 0x192580e8 1 0>,
					<DCC_READ 0x192580f0 1 0>,
					<DCC_READ 0x192580f8 1 0>,
					<DCC_READ 0x19258100 1 0>,
					<DCC_READ 0x19258108 1 0>,
					<DCC_READ 0x19258110 1 0>,
					<DCC_READ 0x19258118 1 0>,
					<DCC_READ 0x19258120 1 0>,
					<DCC_READ 0x19258128 1 0>,
					<DCC_READ 0x19258210 3 0>,
					<DCC_READ 0x19259010 1 0>,
					<DCC_READ 0x19259070 1 0>,
					<DCC_READ 0x1925b004 1 0>,
					<DCC_READ 0x1926004c 1 0>,
					<DCC_READ 0x1926004c 2 0>,
					<DCC_READ 0x19260050 2 0>,
					<DCC_READ 0x19260054 2 0>,
					<DCC_READ 0x19260058 2 0>,
					<DCC_READ 0x1926005c 2 0>,
					<DCC_READ 0x19260060 2 0>,
					<DCC_READ 0x19260064 2 0>,
					<DCC_READ 0x19260068 3 0>,
					<DCC_READ 0x19260078 1 0>,
					<DCC_READ 0x1926020c 1 0>,
					<DCC_READ 0x19260214 1 0>,
					<DCC_READ 0x19261084 1 0>,
					<DCC_READ 0x19262020 1 0>,
					<DCC_READ 0x19263020 1 0>,
					<DCC_READ 0x19264020 1 0>,
					<DCC_READ 0x19265020 1 0>,
					<DCC_READ 0x19320344 2 0>,
					<DCC_READ 0x19320348 8 0>,
					<DCC_READ 0x19320370 7 0>,
					<DCC_READ 0x19320480 1 0>,
					<DCC_READ 0x19320480 1 0>,
					<DCC_READ 0x19322400 1 0>,
					<DCC_READ 0x19322400 26 0>,
					<DCC_READ 0x19322470 5 0>,
					<DCC_READ 0x1932320c 1 0>,
					<DCC_READ 0x19323214 2 0>,
					<DCC_READ 0x19323220 1 0>,
					<DCC_READ 0x19323220 2 0>,
					<DCC_READ 0x19323224 2 0>,
					<DCC_READ 0x19323228 2 0>,
					<DCC_READ 0x1932322c 1 0>,
					<DCC_READ 0x19323308 1 0>,
					<DCC_READ 0x19323308 1 0>,
					<DCC_READ 0x19323318 1 0>,
					<DCC_READ 0x19323318 1 0>,
					<DCC_READ 0x1932358c 1 0>,
					<DCC_READ 0x19334010 1 0>,
					<DCC_READ 0x1933801c 8 0>,
					<DCC_READ 0x19338050 1 0>,
					<DCC_READ 0x19338100 1 0>,
					<DCC_READ 0x19338100 7 0>,
					<DCC_READ 0x1933c004 1 0>,
					<DCC_READ 0x1933c014 1 0>,
					<DCC_READ 0x1933c020 1 0>,
					<DCC_READ 0x1933c030 1 0>,
					<DCC_READ 0x1933c05c 3 0>,
					<DCC_READ 0x1933c074 1 0>,
					<DCC_READ 0x1933c088 1 0>,
					<DCC_READ 0x1933c0a0 1 0>,
					<DCC_READ 0x1933c0b0 1 0>,
					<DCC_READ 0x1933c0c0 1 0>,
					<DCC_READ 0x1933c0d0 1 0>,
					<DCC_READ 0x1933c0e0 1 0>,
					<DCC_READ 0x1933c0f0 1 0>,
					<DCC_READ 0x1933c100 1 0>,
					<DCC_READ 0x1933d064 1 0>,
					<DCC_READ 0x19340008 6 0>,
					<DCC_READ 0x19340028 1 0>,
					<DCC_READ 0x1934203c 3 0>,
					<DCC_READ 0x19342044 2 0>,
					<DCC_READ 0x19342048 2 0>,
					<DCC_READ 0x1934204c 10 0>,
					<DCC_READ 0x1934208c 1 0>,
					<DCC_READ 0x193420b0 1 0>,
					<DCC_READ 0x193420b0 1 0>,
					<DCC_READ 0x193420b8 3 0>,
					<DCC_READ 0x193420f4 1 0>,
					<DCC_READ 0x193420fc 3 0>,
					<DCC_READ 0x19342104 5 0>,
					<DCC_READ 0x19342114 1 0>,
					<DCC_READ 0x19342324 14 0>,
					<DCC_READ 0x19342410 1 0>,
					<DCC_READ 0x193430a8 1 0>,
					<DCC_READ 0x19348004 1 0>,
					<DCC_READ 0x19348004 2 0>,
					<DCC_READ 0x19348008 2 0>,
					<DCC_READ 0x1934800c 2 0>,
					<DCC_READ 0x19348010 4 0>,
					<DCC_READ 0x19348024 1 0>,
					<DCC_READ 0x19348040 1 0>,
					<DCC_READ 0x19348048 1 0>,
					<DCC_READ 0x19349064 1 0>,
					<DCC_READ 0x1934c000 1 0>,
					<DCC_READ 0x1934c030 1 0>,
					<DCC_READ 0x1934c030 3 0>,
					<DCC_READ 0x1934c040 3 0>,
					<DCC_READ 0x1934c054 2 0>,
					<DCC_READ 0x1934c078 1 0>,
					<DCC_READ 0x1934c108 1 0>,
					<DCC_READ 0x1934c110 1 0>,
					<DCC_READ 0x19350020 1 0>,
					<DCC_READ 0x19350020 1 0>,
					<DCC_READ 0x19351054 1 0>,
					<DCC_READ 0x19352014 3 0>,
					<DCC_READ 0x19352028 1 0>,
					<DCC_READ 0x19352028 17 0>,
					<DCC_READ 0x19352070 8 0>,
					<DCC_READ 0x19352098 1 0>,
					<DCC_READ 0x193520a0 1 0>,
					<DCC_READ 0x193520b4 1 0>,
					<DCC_READ 0x193520c0 1 0>,
					<DCC_READ 0x193520d0 3 0>,
					<DCC_READ 0x193520f4 10 0>,
					<DCC_READ 0x19352120 12 0>,
					<DCC_READ 0x1935802c 1 0>,
					<DCC_READ 0x1935802c 1 0>,
					<DCC_READ 0x1935809c 1 0>,
					<DCC_READ 0x1935809c 2 0>,
					<DCC_READ 0x193580a8 3 0>,
					<DCC_READ 0x193580b8 1 0>,
					<DCC_READ 0x193580c0 7 0>,
					<DCC_READ 0x193580e0 1 0>,
					<DCC_READ 0x193580e8 1 0>,
					<DCC_READ 0x193580f0 1 0>,
					<DCC_READ 0x193580f8 1 0>,
					<DCC_READ 0x193580a0 1 0>,
					<DCC_READ 0x193580a8 3 0>,
					<DCC_READ 0x193580b8 1 0>,
					<DCC_READ 0x193580c0 7 0>,
					<DCC_READ 0x193580e0 1 0>,
					<DCC_READ 0x193580e8 1 0>,
					<DCC_READ 0x193580f0 1 0>,
					<DCC_READ 0x193580f8 1 0>,
					<DCC_READ 0x19358100 1 0>,
					<DCC_READ 0x19358100 1 0>,
					<DCC_READ 0x19358108 1 0>,
					<DCC_READ 0x19358108 1 0>,
					<DCC_READ 0x19358110 1 0>,
					<DCC_READ 0x19358110 1 0>,
					<DCC_READ 0x19358118 1 0>,
					<DCC_READ 0x19358118 1 0>,
					<DCC_READ 0x19358120 1 0>,
					<DCC_READ 0x19358120 1 0>,
					<DCC_READ 0x19358128 1 0>,
					<DCC_READ 0x19358128 1 0>,
					<DCC_READ 0x19358210 1 0>,
					<DCC_READ 0x19358210 2 0>,
					<DCC_READ 0x19358214 2 0>,
					<DCC_READ 0x19358218 1 0>,
					<DCC_READ 0x19359010 1 0>,
					<DCC_READ 0x19359010 1 0>,
					<DCC_READ 0x19359070 1 0>,
					<DCC_READ 0x19359070 1 0>,
					<DCC_READ 0x1935b004 1 0>,
					<DCC_READ 0x1935b004 1 0>,
					<DCC_READ 0x1936004c 1 0>,
					<DCC_READ 0x1936004c 1 0>,
					<DCC_READ 0x1936004c 2 0>,
					<DCC_READ 0x19360050 1 0>,
					<DCC_READ 0x19360050 2 0>,
					<DCC_READ 0x19360054 1 0>,
					<DCC_READ 0x19360054 2 0>,
					<DCC_READ 0x19360058 1 0>,
					<DCC_READ 0x19360058 2 0>,
					<DCC_READ 0x1936005c 1 0>,
					<DCC_READ 0x1936005c 2 0>,
					<DCC_READ 0x19360060 1 0>,
					<DCC_READ 0x19360060 2 0>,
					<DCC_READ 0x19360064 1 0>,
					<DCC_READ 0x19360064 2 0>,
					<DCC_READ 0x19360068 1 0>,
					<DCC_READ 0x19360068 3 0>,
					<DCC_READ 0x19360078 1 0>,
					<DCC_READ 0x1936020c 1 0>,
					<DCC_READ 0x19360214 1 0>,
					<DCC_READ 0x19361084 1 0>,
					<DCC_READ 0x19362020 1 0>,
					<DCC_READ 0x19363020 1 0>,
					<DCC_READ 0x19364020 1 0>,
					<DCC_READ 0x19365020 1 0>,
					<DCC_READ 0x19200004 1 0>,
					<DCC_READ 0x19201004 1 0>,
					<DCC_READ 0x19202004 1 0>,
					<DCC_READ 0x19203004 1 0>,
					<DCC_READ 0x19204004 1 0>,
					<DCC_READ 0x19205004 1 0>,
					<DCC_READ 0x19206004 1 0>,
					<DCC_READ 0x19207004 1 0>,
					<DCC_READ 0x19208004 1 0>,
					<DCC_READ 0x19209004 1 0>,
					<DCC_READ 0x1920a004 1 0>,
					<DCC_READ 0x1920b004 1 0>,
					<DCC_READ 0x1920c004 1 0>,
					<DCC_READ 0x1920d004 1 0>,
					<DCC_READ 0x1920e004 1 0>,
					<DCC_READ 0x1920f004 1 0>,
					<DCC_READ 0x19210004 1 0>,
					<DCC_READ 0x19211004 1 0>,
					<DCC_READ 0x19212004 1 0>,
					<DCC_READ 0x19213004 1 0>,
					<DCC_READ 0x19214004 1 0>,
					<DCC_READ 0x19215004 1 0>,
					<DCC_READ 0x19216004 1 0>,
					<DCC_READ 0x19217004 1 0>,
					<DCC_READ 0x19218004 1 0>,
					<DCC_READ 0x19219004 1 0>,
					<DCC_READ 0x1921a004 1 0>,
					<DCC_READ 0x1921b004 1 0>,
					<DCC_READ 0x1921c004 1 0>,
					<DCC_READ 0x1921d004 1 0>,
					<DCC_READ 0x1921e004 1 0>,
					<DCC_READ 0x1921f004 1 0>,
					<DCC_READ 0x192c5cac 3 0>,
					<DCC_READ 0x192c0080 1 0>,
					<DCC_READ 0x192c0310 1 0>,
					<DCC_READ 0x192c0400 2 0>,
					<DCC_READ 0x192c0410 6 0>,
					<DCC_READ 0x192c0430 1 0>,
					<DCC_READ 0x192c0440 1 0>,
					<DCC_READ 0x192c0448 1 0>,
					<DCC_READ 0x192c04a0 1 0>,
					<DCC_READ 0x192c04b0 4 0>,
					<DCC_READ 0x192c04d0 2 0>,
					<DCC_READ 0x192c1400 1 0>,
					<DCC_READ 0x192c1408 1 0>,
					<DCC_READ 0x192c2400 2 0>,
					<DCC_READ 0x192c2438 2 0>,
					<DCC_READ 0x192c2454 1 0>,
					<DCC_READ 0x192c3400 4 0>,
					<DCC_READ 0x192c3418 3 0>,
					<DCC_READ 0x192c4700 1 0>,
					<DCC_READ 0x192c53b0 1 0>,
					<DCC_READ 0x192c5804 1 0>,
					<DCC_READ 0x192c590c 1 0>,
					<DCC_READ 0x192c5a14 1 0>,
					<DCC_READ 0x192c5c0c 1 0>,
					<DCC_READ 0x192c5c18 2 0>,
					<DCC_READ 0x192c5c2c 2 0>,
					<DCC_READ 0x192c5c38 1 0>,
					<DCC_READ 0x192c5c4c 1 0>,
					<DCC_READ 0x192c5ca4 1 0>,
					<DCC_READ 0x192c5cac 3 0>,
					<DCC_READ 0x192c6400 1 0>,
					<DCC_READ 0x192c6418 2 0>,
					<DCC_READ 0x192c9100 1 0>,
					<DCC_READ 0x192c9110 1 0>,
					<DCC_READ 0x192c9120 1 0>,
					<DCC_READ 0x192c9180 1 0>,
					<DCC_READ 0x192c9180 2 0>,
					<DCC_READ 0x192c9184 1 0>,
					<DCC_READ 0x192c91a0 1 0>,
					<DCC_READ 0x192c91b0 1 0>,
					<DCC_READ 0x192c91c0 2 0>,
					<DCC_READ 0x192c91e0 1 0>,
					<DCC_READ 0x190ba280 1 0>,
					<DCC_READ 0x190ba288 8 0>,
					<DCC_READ 0x192e0610 4 0>,
					<DCC_READ 0x192e0680 4 0>,
					<DCC_READ 0x19281e64 1 0>,
					<DCC_READ 0x19281ea0 1 0>,
					<DCC_READ 0x19281f30 2 0>,
					<DCC_READ 0x19283e64 1 0>,
					<DCC_READ 0x19283ea0 1 0>,
					<DCC_READ 0x19283f30 2 0>,
					<DCC_READ 0x1928527c 1 0>,
					<DCC_READ 0x19285290 1 0>,
					<DCC_READ 0x192854ec 1 0>,
					<DCC_READ 0x192854f4 1 0>,
					<DCC_READ 0x19285514 1 0>,
					<DCC_READ 0x1928551c 1 0>,
					<DCC_READ 0x19285524 1 0>,
					<DCC_READ 0x19285548 1 0>,
					<DCC_READ 0x19285550 1 0>,
					<DCC_READ 0x19285558 1 0>,
					<DCC_READ 0x192855b8 1 0>,
					<DCC_READ 0x192855c0 1 0>,
					<DCC_READ 0x192855ec 1 0>,
					<DCC_READ 0x19285860 1 0>,
					<DCC_READ 0x19285870 1 0>,
					<DCC_READ 0x192858a0 1 0>,
					<DCC_READ 0x192858a8 1 0>,
					<DCC_READ 0x192858b0 1 0>,
					<DCC_READ 0x192858b8 1 0>,
					<DCC_READ 0x192858d8 2 0>,
					<DCC_READ 0x192858f4 1 0>,
					<DCC_READ 0x192858fc 1 0>,
					<DCC_READ 0x19285920 1 0>,
					<DCC_READ 0x19285928 1 0>,
					<DCC_READ 0x19285944 1 0>,
					<DCC_READ 0x19286604 1 0>,
					<DCC_READ 0x1928660c 1 0>,
					<DCC_READ 0x19032020 1 0>,
					<DCC_READ 0x19032024 1 0>,
					<DCC_READ 0x1908e01c 1 0>,
					<DCC_READ 0x1908e030 1 0>,
					<DCC_READ 0x19030010 1 0>,
					<DCC_READ 0x1908e008 1 0>,
					<DCC_READ 0x19032020 1 0>,
					<DCC_READ 0x1908e948 1 0>,
					<DCC_READ 0x19032024 1 0>,
					<DCC_WRITE 0x19030040 0x1 1>,
					<DCC_WRITE 0x1903005c 0x22C000 1>,
					<DCC_READ 0x19030010 1 0>,
					<DCC_WRITE 0x1903005c 0x22C001 1>,
					<DCC_READ 0x19030010 1 0>,
					<DCC_WRITE 0x1903005c 0x22C002 1>,
					<DCC_READ 0x19030010 1 0>,
					<DCC_WRITE 0x1903005c 0x22C003 1>,
					<DCC_READ 0x19030010 1 0>,
					<DCC_WRITE 0x1903005c 0x22C004 1>,
					<DCC_READ 0x19030010 1 0>,
					<DCC_WRITE 0x1903005c 0x22C005 1>,
					<DCC_READ 0x19030010 1 0>,
					<DCC_WRITE 0x1903005c 0x22C006 1>,
					<DCC_READ 0x19030010 1 0>,
					<DCC_WRITE 0x1903005c 0x22C007 1>,
					<DCC_READ 0x19030010 1 0>,
					<DCC_WRITE 0x1903005c 0x22C008 1>,
					<DCC_READ 0x19030010 1 0>,
					<DCC_WRITE 0x1903005c 0x22C009 1>,
					<DCC_READ 0x19030010 1 0>,
					<DCC_WRITE 0x1903005c 0x22C00A 1>,
					<DCC_READ 0x19030010 1 0>,
					<DCC_WRITE 0x1903005c 0x22C00B 1>,
					<DCC_READ 0x19030010 1 0>,
					<DCC_WRITE 0x1903005c 0x22C00C 1>,
					<DCC_READ 0x19030010 1 0>,
					<DCC_WRITE 0x1903005c 0x22C00D 1>,
					<DCC_READ 0x19030010 1 0>,
					<DCC_WRITE 0x1903005c 0x22C00E 1>,
					<DCC_READ 0x19030010 1 0>,
					<DCC_WRITE 0x1903005c 0x22C00F 1>,
					<DCC_READ 0x19030010 1 0>,
					<DCC_WRITE 0x1903005c 0x22C010 1>,
					<DCC_READ 0x19030010 1 0>,
					<DCC_WRITE 0x1903005c 0x22C011 1>,
					<DCC_READ 0x19030010 1 0>,
					<DCC_WRITE 0x1903005c 0x22C012 1>,
					<DCC_READ 0x19030010 1 0>,
					<DCC_WRITE 0x1903005c 0x22C013 1>,
					<DCC_READ 0x19030010 1 0>,
					<DCC_WRITE 0x1903005c 0x22C014 1>,
					<DCC_READ 0x19030010 1 0>,
					<DCC_WRITE 0x1903005c 0x22C015 1>,
					<DCC_READ 0x19030010 1 0>,
					<DCC_WRITE 0x1903005c 0x22C016 1>,
					<DCC_READ 0x19030010 1 0>,
					<DCC_WRITE 0x1903005c 0x22C017 1>,
					<DCC_READ 0x19030010 1 0>,
					<DCC_WRITE 0x1903005c 0x22C018 1>,
					<DCC_READ 0x19030010 1 0>,
					<DCC_WRITE 0x1903005c 0x22C019 1>,
					<DCC_READ 0x19030010 1 0>,
					<DCC_WRITE 0x1903005c 0x22C01A 1>,
					<DCC_READ 0x19030010 1 0>,
					<DCC_WRITE 0x1903005c 0x22C01B 1>,
					<DCC_READ 0x19030010 1 0>,
					<DCC_WRITE 0x1903005c 0x22C01C 1>,
					<DCC_READ 0x19030010 1 0>,
					<DCC_WRITE 0x1903005c 0x22C01D 1>,
					<DCC_READ 0x19030010 1 0>,
					<DCC_WRITE 0x1903005c 0x22C01E 1>,
					<DCC_READ 0x19030010 1 0>,
					<DCC_WRITE 0x1903005c 0x22C01F 1>,
					<DCC_READ 0x19030010 1 0>,
					<DCC_WRITE 0x1903005c 0x22C300 1>,
					<DCC_READ 0x19030010 1 0>,
					<DCC_WRITE 0x1903005c 0x22C341 1>,
					<DCC_READ 0x19030010 1 0>,
					<DCC_WRITE 0x1903005c 0x22C7B1 1>,
					<DCC_READ 0x19030010 1 0>,
					<DCC_READ 0x191920A0 1 0>,
					<DCC_READ 0x191920A8 1 0>;
				};

		link_list_1 {
			qcom,curr-link-list = <4>;
			qcom,data-sink = "sram";
			qcom,link-list = <DCC_READ 0x17200104 29 0>,
					<DCC_READ 0x17200204 29 0>,
					<DCC_READ 0x17200384 29 0>,
					<DCC_READ 0x100000 1 0>,
					<DCC_READ 0x100004 1 0>,
					<DCC_READ 0x101000 1 0>,
					<DCC_READ 0x101004 1 0>,
					<DCC_READ 0x102000 1 0>,
					<DCC_READ 0x102004 1 0>,
					<DCC_READ 0x103000 1 0>,
					<DCC_READ 0x103004 1 0>,
					<DCC_READ 0x104000 1 0>,
					<DCC_READ 0x104004 1 0>,
					<DCC_READ 0x105000 1 0>,
					<DCC_READ 0x105004 1 0>,
					<DCC_READ 0x106000 1 0>,
					<DCC_READ 0x106004 1 0>,
					<DCC_READ 0x107000 1 0>,
					<DCC_READ 0x107004 1 0>,
					<DCC_READ 0x108000 1 0>,
					<DCC_READ 0x108004 1 0>,
					<DCC_READ 0x109000 1 0>,
					<DCC_READ 0x109004 1 0>,
					<DCC_READ 0xc2a0000 1 0>,
					<DCC_READ 0xc2a0004 1 0>,
					<DCC_READ 0xc2a1000 1 0>,
					<DCC_READ 0xc2a1004 1 0>,
					<DCC_READ 0xc2b100c 1 0>,
					<DCC_READ 0x12802c 1 0>,
					<DCC_READ 0x128164 1 0>,
					<DCC_READ 0x12829c 1 0>,
					<DCC_READ 0x1283d4 1 0>,
					<DCC_READ 0x12850c 1 0>,
					<DCC_READ 0x128644 1 0>,
					<DCC_READ 0x12e02c 1 0>,
					<DCC_READ 0x12e164 1 0>,
					<DCC_READ 0x12e29c 1 0>,
					<DCC_READ 0x12e3d4 1 0>,
					<DCC_READ 0x12e50c 1 0>,
					<DCC_READ 0x12e644 1 0>,
					<DCC_READ 0x155028 1 0>,
					<DCC_READ 0x15102c 1 0>,
					<DCC_READ 0x184058 1 0>,
					<DCC_READ 0x12c094 1 0>,
					<DCC_READ 0x146020 1 0>,
					<DCC_READ 0x133054 1 0>,
					<DCC_READ 0x15416c 1 0>,
					<DCC_READ 0x193028 1 0>,
					<DCC_READ 0x186048 1 0>,
					<DCC_READ 0x120004 1 0>,
					<DCC_READ 0x120008 1 0>,
					<DCC_READ 0x12c004 1 0>,
					<DCC_READ 0x12c008 1 0>,
					<DCC_READ 0x17b004 1 0>,
					<DCC_READ 0x17b008 1 0>,
					<DCC_READ 0x17c000 1 0>,
					<DCC_READ 0x17c004 1 0>,
					<DCC_READ 0x19d004 1 0>,
					<DCC_READ 0x19d008 1 0>,
					<DCC_READ 0x19e000 1 0>,
					<DCC_READ 0x19e004 1 0>,
					<DCC_READ 0x1ad000 1 0>,
					<DCC_READ 0x1ad004 1 0>,
					<DCC_READ 0x149008 1 0>,
					<DCC_READ 0x149004 1 0>,
					<DCC_READ 0x160018 1 0>,
					<DCC_READ 0x16001c 1 0>,
					<DCC_READ 0x162000 1 0>,
					<DCC_READ 0x162008 1 0>,
					<DCC_READ 0x162010 1 0>,
					<DCC_READ 0x163024 1 0>,
					<DCC_READ 0x16302c 1 0>,
					<DCC_READ 0x163034 1 0>,
					<DCC_READ 0x166000 1 0>,
					<DCC_READ 0x166008 1 0>,
					<DCC_READ 0x166010 1 0>,
					<DCC_READ 0x166204 1 0>,
					<DCC_READ 0x165000 1 0>,
					<DCC_READ 0x165008 1 0>,
					<DCC_READ 0x165010 1 0>,
					<DCC_READ 0x161000 1 0>,
					<DCC_READ 0x161008 1 0>,
					<DCC_READ 0x161010 1 0>,
					<DCC_READ 0x16a000 1 0>,
					<DCC_READ 0x16a008 1 0>,
					<DCC_READ 0x16a010 1 0>,
					<DCC_READ 0x167000 1 0>,
					<DCC_READ 0x167008 1 0>,
					<DCC_READ 0x167010 1 0>,
					<DCC_READ 0x179024 1 0>,
					<DCC_READ 0x17902c 1 0>,
					<DCC_READ 0x179034 1 0>,
					<DCC_READ 0x16b000 1 0>,
					<DCC_READ 0x16b008 1 0>,
					<DCC_READ 0x16b010 1 0>,
					<DCC_READ 0x1b1024 1 0>,
					<DCC_READ 0x1b102c 1 0>,
					<DCC_READ 0x1b1034 1 0>,
					<DCC_READ 0x120024 1 0>,
					<DCC_READ 0x12c038 1 0>,
					<DCC_READ 0x12c044 1 0>,
					<DCC_READ 0x12c050 1 0>,
					<DCC_READ 0x12c05c 1 0>,
					<DCC_READ 0x12c068 1 0>,
					<DCC_READ 0x12c074 1 0>,
					<DCC_READ 0x157004 1 0>,
					<DCC_READ 0x1a0004 1 0>,
					<DCC_READ 0x1a0010 1 0>,
					<DCC_READ 0x1ad014 1 0>,
					<DCC_READ 0x1ad020 1 0>,
					<DCC_READ 0x193004 1 0>,
					<DCC_READ 0x193008 1 0>,
					<DCC_READ 0x193144 1 0>,
					<DCC_READ 0x18400C 1 0>,
					<DCC_READ 0x184018 1 0>,
					<DCC_READ 0x18401C 1 0>,
					<DCC_READ 0x17B038 1 0>,
					<DCC_READ 0x17B02C 1 0>,
					<DCC_READ 0x17B054 1 0>,
					<DCC_READ 0x17B048 1 0>,
					<DCC_READ 0x17B020 1 0>,
					<DCC_READ 0x17B01C 1 0>,
					<DCC_READ 0x129114 1 0>,
					<DCC_READ 0x129214 1 0>,
					<DCC_READ 0x18B114 1 0>,
					<DCC_READ 0x18B214 1 0>,
					<DCC_READ 0x18C114 1 0>,
					<DCC_READ 0x18C214 1 0>,
					<DCC_READ 0x18D114 1 0>,
					<DCC_READ 0x18D214 1 0>,
					<DCC_READ 0x18E114 1 0>,
					<DCC_READ 0x18E214 1 0>,
					<DCC_READ 0x121004 5 0>,
					<DCC_READ 0x151d0008 1 0>,
					<DCC_READ 0x150025dc 1 0>,
					<DCC_READ 0x150055dc 1 0>,
					<DCC_READ 0x150075dc 1 0>,
					<DCC_READ 0x150075dc 1 0>,
					<DCC_READ 0x15002204 1 0>,
					<DCC_READ 0x15002670 1 0>,
					<DCC_READ 0x15002648 1 0>,
					<DCC_READ 0x150022fc 1 0>,
					<DCC_READ 0x15002300 1 0>,
					<DCC_READ 0x15002304 1 0>,
					<DCC_READ 0x150022fc 1 0>,
					<DCC_READ 0x15002304 1 0>,
					<DCC_READ 0x19100010 1 0>,
					<DCC_READ 0x19100020 1 0>,
					<DCC_READ 0x19100024 1 0>,
					<DCC_READ 0x19100028 1 0>,
					<DCC_READ 0x1910002c 1 0>,
					<DCC_READ 0x19100030 1 0>,
					<DCC_READ 0x19100034 1 0>,
					<DCC_READ 0x19140010 1 0>,
					<DCC_READ 0x19140020 1 0>,
					<DCC_READ 0x19140024 1 0>,
					<DCC_READ 0x19140028 1 0>,
					<DCC_READ 0x1914002c 1 0>,
					<DCC_READ 0x19140030 1 0>,
					<DCC_READ 0x19140034 1 0>,
					<DCC_READ 0x19180010 1 0>,
					<DCC_READ 0x19180020 1 0>,
					<DCC_READ 0x19180024 1 0>,
					<DCC_READ 0x19180028 1 0>,
					<DCC_READ 0x1918002c 1 0>,
					<DCC_READ 0x19180030 1 0>,
					<DCC_READ 0x19180034 1 0>,
					<DCC_READ 0x19180410 1 0>,
					<DCC_READ 0x19180420 1 0>,
					<DCC_READ 0x19180424 1 0>,
					<DCC_READ 0x19180428 1 0>,
					<DCC_READ 0x1918042c 1 0>,
					<DCC_READ 0x19180430 1 0>,
					<DCC_READ 0x19180434 1 0>,
					<DCC_READ 0x19180848 1 0>,
					<DCC_READ 0x1910e010 1 0>,
					<DCC_READ 0x1910f010 1 0>,
					<DCC_READ 0x19110010 1 0>,
					<DCC_READ 0x1914e010 1 0>,
					<DCC_READ 0x1914f010 1 0>,
					<DCC_READ 0x19150010 1 0>,
					<DCC_READ 0x1919c010 1 0>,
					<DCC_READ 0x1919d010 1 0>,
					<DCC_READ 0x1919e010 1 0>,
					<DCC_READ 0x1919f010 1 0>,
					<DCC_READ 0x191a0010 1 0>,
					<DCC_READ 0x191a1010 1 0>,
					<DCC_READ 0x191a2010 1 0>,
					<DCC_READ 0x19102018 1 0>,
					<DCC_READ 0x19102008 1 0>,
					<DCC_LOOP 0x3  0 0>,
					<DCC_READ 0x19102010 2 0>,
					<DCC_LOOP 0x1  0 0>,
					<DCC_READ 0x19102098 1 0>,
					<DCC_READ 0x19102088 1 0>,
					<DCC_LOOP 0x4  0 0>,
					<DCC_READ 0x19102090 2 0>,
					<DCC_LOOP 0x1  0 0>,
					<DCC_READ 0x19142018 1 0>,
					<DCC_READ 0x19142008 1 0>,
					<DCC_LOOP 0x3  0 0>,
					<DCC_READ 0x19142010 2 0>,
					<DCC_LOOP 0x1  0 0>,
					<DCC_READ 0x19142098 1 0>,
					<DCC_READ 0x19142088 1 0>,
					<DCC_LOOP 0x4  0 0>,
					<DCC_READ 0x19142090 2 0>,
					<DCC_LOOP 0x1  0 0>,
					<DCC_READ 0x19182018 1 0>,
					<DCC_READ 0x19182008 1 0>,
					<DCC_LOOP 0x3  0 0>,
					<DCC_READ 0x19182010 2 0>,
					<DCC_LOOP 0x1  0 0>,
					<DCC_READ 0x19182098 1 0>,
					<DCC_READ 0x19182088 1 0>,
					<DCC_LOOP 0x9  0 0>,
					<DCC_READ 0x19182090 2 0>,
					<DCC_LOOP 0x1  0 0>,
					<DCC_READ 0x1500010 1 0>,
					<DCC_READ 0x1500020 1 0>,
					<DCC_READ 0x1500024 1 0>,
					<DCC_READ 0x1500028 1 0>,
					<DCC_READ 0x150002c 1 0>,
					<DCC_READ 0x1500030 1 0>,
					<DCC_READ 0x1500034 1 0>,
					<DCC_READ 0x1500038 1 0>,
					<DCC_READ 0x150003c 1 0>,
					<DCC_READ 0x1500248 1 0>,
					<DCC_READ 0x150024c 1 0>,
					<DCC_READ 0x1500258 1 0>,
					<DCC_READ 0x1500448 1 0>,
					<DCC_READ 0x1502018 1 0>,
					<DCC_READ 0x1502008 1 0>,
					<DCC_LOOP 0x13  0 0>,
					<DCC_READ 0x1502010 2 0>,
					<DCC_LOOP 0x1  0 0>,
					<DCC_READ 0x1502098 1 0>,
					<DCC_READ 0x1502088 1 0>,
					<DCC_LOOP 0x2  0 0>,
					<DCC_READ 0x1502090 2 0>,
					<DCC_LOOP 0x1  0 0>,
					<DCC_READ 0x1502118 1 0>,
					<DCC_READ 0x1502108 1 0>,
					<DCC_LOOP 0x3  0 0>,
					<DCC_READ 0x1502110 2 0>,
					<DCC_LOOP 0x1  0 0>,
					<DCC_READ 0x1502198 1 0>,
					<DCC_READ 0x1502188 1 0>,
					<DCC_LOOP 0x5  0 0>,
					<DCC_READ 0x1502190 2 0>,
					<DCC_LOOP 0x1  0 0>,
					<DCC_READ 0x1680010 1 0>,
					<DCC_READ 0x1680020 1 0>,
					<DCC_READ 0x1680024 1 0>,
					<DCC_READ 0x1680028 1 0>,
					<DCC_READ 0x168002c 1 0>,
					<DCC_READ 0x1680030 1 0>,
					<DCC_READ 0x1680034 1 0>,
					<DCC_READ 0x1680038 1 0>,
					<DCC_READ 0x168003c 1 0>,
					<DCC_READ 0x1680248 1 0>,
					<DCC_READ 0x1681018 1 0>,
					<DCC_READ 0x1681008 1 0>,
					<DCC_LOOP 0x9  0 0>,
					<DCC_READ 0x1681010 2 0>,
					<DCC_LOOP 0x1  0 0>,
					<DCC_READ 0x1681098 1 0>,
					<DCC_READ 0x1681088 1 0>,
					<DCC_LOOP 0x3  0 0>,
					<DCC_READ 0x1681090 2 0>,
					<DCC_LOOP 0x1  0 0>,
					<DCC_READ 0x1740010 1 0>,
					<DCC_READ 0x1740020 1 0>,
					<DCC_READ 0x1740024 1 0>,
					<DCC_READ 0x1740028 1 0>,
					<DCC_READ 0x174002c 1 0>,
					<DCC_READ 0x1740030 1 0>,
					<DCC_READ 0x1740034 1 0>,
					<DCC_READ 0x1740038 1 0>,
					<DCC_READ 0x174003c 1 0>,
					<DCC_READ 0x1740248 1 0>,
					<DCC_READ 0x1741018 1 0>,
					<DCC_READ 0x1741008 1 0>,
					<DCC_LOOP 0x10  0 0>,
					<DCC_READ 0x1741010 2 0>,
					<DCC_LOOP 0x1  0 0>,
					<DCC_READ 0x3c40010 1 0>,
					<DCC_READ 0x3c40020 1 0>,
					<DCC_READ 0x3c40024 1 0>,
					<DCC_READ 0x3c40028 1 0>,
					<DCC_READ 0x3c4002c 1 0>,
					<DCC_READ 0x3c40030 1 0>,
					<DCC_READ 0x3c40034 1 0>,
					<DCC_READ 0x3c40038 1 0>,
					<DCC_READ 0x3c4003c 1 0>,
					<DCC_READ 0x3c4b048 1 0>,
					<DCC_READ 0x3c41018 1 0>,
					<DCC_READ 0x3c41008 1 0>,
					<DCC_LOOP 0x4  0 0>,
					<DCC_READ 0x3c41010 2 0>,
					<DCC_LOOP 0x1  0 0>,
					<DCC_READ 0x190e0010 1 0>,
					<DCC_READ 0x190e0020 1 0>,
					<DCC_READ 0x190e0024 1 0>,
					<DCC_READ 0x190e0028 1 0>,
					<DCC_READ 0x190e002c 1 0>,
					<DCC_READ 0x190e0030 1 0>,
					<DCC_READ 0x190e0034 1 0>,
					<DCC_READ 0x190e0038 1 0>,
					<DCC_READ 0x190e003c 1 0>,
					<DCC_READ 0x190e0248 1 0>,
					<DCC_READ 0x190e5018 1 0>,
					<DCC_READ 0x190e5008 1 0>,
					<DCC_LOOP 0x7  0 0>,
					<DCC_READ 0x190e5010 2 0>,
					<DCC_LOOP 0x1  0 0>,
					<DCC_READ 0x195f0010 1 0>,
					<DCC_READ 0x195f0020 1 0>,
					<DCC_READ 0x195f0024 1 0>,
					<DCC_READ 0x195f0028 1 0>,
					<DCC_READ 0x195f002c 1 0>,
					<DCC_READ 0x195f0030 1 0>,
					<DCC_READ 0x195f0034 1 0>,
					<DCC_READ 0x195f0038 1 0>,
					<DCC_READ 0x195f003c 1 0>,
					<DCC_READ 0x195f0248 1 0>,
					<DCC_READ 0x195f2018 1 0>,
					<DCC_READ 0x195f2008 1 0>,
					<DCC_LOOP 0x3  0 0>,
					<DCC_READ 0x195f2010 2 0>,
					<DCC_LOOP 0x1  0 0>,
					<DCC_READ 0x19101010 1 0>,
					<DCC_LOOP 0x40 0 0>,
					<DCC_READ 0x19101038 1 0>,
					<DCC_READ 0x19101030 2 0>,
					<DCC_READ 0x19101030 2 0>,
					<DCC_READ 0x19101030 2 0>,
					<DCC_READ 0x19101030 2 0>,
					<DCC_LOOP 0x1 0 0>,
					<DCC_READ 0x19141010 1 0>,
					<DCC_LOOP 0x40 0 0>,
					<DCC_READ 0x19141038 1 0>,
					<DCC_READ 0x19141030 2 0>,
					<DCC_READ 0x19141030 2 0>,
					<DCC_READ 0x19141030 2 0>,
					<DCC_READ 0x19141030 2 0>,
					<DCC_LOOP 0x1 0 0>,
					<DCC_READ 0x19181010 1 0>,
					<DCC_LOOP 0x40 0 0>,
					<DCC_READ 0x19181038 1 0>,
					<DCC_READ 0x19181030 2 0>,
					<DCC_READ 0x19181030 2 0>,
					<DCC_READ 0x19181030 2 0>,
					<DCC_READ 0x19181030 2 0>,
					<DCC_LOOP 0x1 0 0>,
					<DCC_READ 0x19181410 1 0>,
					<DCC_LOOP 0x40 0 0>,
					<DCC_READ 0x19181438 1 0>,
					<DCC_READ 0x19181430 2 0>,
					<DCC_READ 0x19181430 2 0>,
					<DCC_READ 0x19181430 2 0>,
					<DCC_READ 0x19181430 2 0>,
					<DCC_LOOP 0x1 0 0>,
					<DCC_READ 0x30b0208 1 0>,
					<DCC_READ 0x30b0228 1 0>,
					<DCC_READ 0x30b0248 1 0>,
					<DCC_READ 0x30b0268 1 0>,
					<DCC_READ 0x30b0288 1 0>,
					<DCC_READ 0x30b02a8 1 0>,
					<DCC_READ 0x30b020c 1 0>,
					<DCC_READ 0x30b022c 1 0>,
					<DCC_READ 0x30b024c 1 0>,
					<DCC_READ 0x30b026c 1 0>,
					<DCC_READ 0x30b028c 1 0>,
					<DCC_READ 0x30b02ac 1 0>,
					<DCC_READ 0x30b0210 1 0>,
					<DCC_READ 0x30b0230 1 0>,
					<DCC_READ 0x30b0250 1 0>,
					<DCC_READ 0x30b0270 1 0>,
					<DCC_READ 0x30b0290 1 0>,
					<DCC_READ 0x30b02b0 1 0>,
					<DCC_READ 0x30b0400 1 0>,
					<DCC_READ 0x30b0404 1 0>,
					<DCC_READ 0x30b0408 1 0>,
					<DCC_READ 0x3480400 1 0>,
					<DCC_READ 0x3480404 1 0>,
					<DCC_READ 0x3480408 1 0>,
					<DCC_READ 0x3002028 1 0>,
					<DCC_READ 0x3000304 1 0>,
					<DCC_READ 0x8ab0208 1 0>,
					<DCC_READ 0x8ab0228 1 0>,
					<DCC_READ 0x8ab0248 1 0>,
					<DCC_READ 0x8ab0268 1 0>,
					<DCC_READ 0x8ab0288 1 0>,
					<DCC_READ 0x8ab02a8 1 0>,
					<DCC_READ 0x8ab020c 1 0>,
					<DCC_READ 0x8ab022c 1 0>,
					<DCC_READ 0x8ab024c 1 0>,
					<DCC_READ 0x8ab026c 1 0>,
					<DCC_READ 0x8ab028c 1 0>,
					<DCC_READ 0x8ab02ac 1 0>,
					<DCC_READ 0x8ab0210 1 0>,
					<DCC_READ 0x8ab0230 1 0>,
					<DCC_READ 0x8ab0250 1 0>,
					<DCC_READ 0x8ab0270 1 0>,
					<DCC_READ 0x8ab0290 1 0>,
					<DCC_READ 0x8ab02b0 1 0>,
					<DCC_READ 0x8ab0400 1 0>,
					<DCC_READ 0x8ab0404 1 0>,
					<DCC_READ 0x8ab0408 1 0>,
					<DCC_READ 0x8b00400 1 0>,
					<DCC_READ 0x8b00404 1 0>,
					<DCC_READ 0x8b00408 1 0>,
					<DCC_READ 0x8a02028 1 0>,
					<DCC_READ 0x8a00304 1 0>,
					<DCC_READ 0x13316c 1 0>,
					<DCC_READ 0x13317c 1 0>,
					<DCC_READ 0x128004 1 0>,
					<DCC_READ 0x128008 1 0>,
					<DCC_READ 0x12e008 1 0>,
					<DCC_READ 0x12e00c 1 0>,
					<DCC_READ 0x12e144 1 0>,
					<DCC_READ 0x12e27c 1 0>,
					<DCC_READ 0x12e3b4 1 0>,
					<DCC_READ 0x12e4ec 1 0>,
					<DCC_READ 0x12e624 1 0>;
			};
	};

	mem_dump {
		compatible = "qcom,mem-dump";
		memory-region = <&dump_mem>;

		c0_context {
			qcom,dump-size = <0x800>;
			qcom,dump-id = <0x0>;
		};

		c100_context {
			qcom,dump-size = <0x800>;
			qcom,dump-id = <0x1>;
		};

		c200_context {
			qcom,dump-size = <0x800>;
			qcom,dump-id = <0x2>;
		};

		c300_context {
			qcom,dump-size = <0x800>;
			qcom,dump-id = <0x3>;
		};

		cpuss_reg {
			qcom,dump-size = <0x30000>;
			qcom,dump-id = <0xef>;
		};

		l1_icache0 {
			qcom,dump-size = <0x21200>;
			qcom,dump-id = <0x60>;
		};

		l1_icache100 {
			qcom,dump-size = <0x21200>;
			qcom,dump-id = <0x61>;
		};

		l1_icache200 {
			qcom,dump-size = <0x21200>;
			qcom,dump-id = <0x62>;
		};

		l1_icache300 {
			qcom,dump-size = <0x21200>;
			qcom,dump-id = <0x63>;
		};

		l1_dcache0 {
			qcom,dump-size = <0x12200>;
			qcom,dump-id = <0x80>;
		};

		l1_dcache100 {
			qcom,dump-size = <0x12200>;
			qcom,dump-id = <0x81>;
		};

		l1_dcache200 {
			qcom,dump-size = <0x12200>;
			qcom,dump-id = <0x82>;
		};

		l1_dcache300 {
			qcom,dump-size = <0x12200>;
			qcom,dump-id = <0x83>;
		};

		l2_tlb0 {
			qcom,dump-size = <0x5b00>;
			qcom,dump-id = <0x120>;
		};

		l2_tlb100 {
			qcom,dump-size = <0x5b00>;
			qcom,dump-id = <0x121>;
		};

		l2_tlb200 {
			qcom,dump-size = <0x5b00>;
			qcom,dump-id = <0x122>;
		};

		l2_tlb300 {
			qcom,dump-size = <0x5b00>;
			qcom,dump-id = <0x123>;
		};

		rpmh {
			qcom,dump-size = <0x400000>;
			qcom,dump-id = <0xec>;
		};

		rpm_sw {
			qcom,dump-size = <0x28000>;
			qcom,dump-id = <0xea>;
		};

		pmic {
			qcom,dump-size = <0x200000>;
			qcom,dump-id = <0xe4>;
		};

		fcm {
			qcom,dump-size = <0x8400>;
			qcom,dump-id = <0xee>;
		};

		etf_swao {
			qcom,dump-size = <0x10000>;
			qcom,dump-id = <0xf1>;
		};

		etr_reg {
			qcom,dump-size = <0x1000>;
			qcom,dump-id = <0x100>;
		};

		etfswao_reg {
			qcom,dump-size = <0x1000>;
			qcom,dump-id = <0x102>;
		};

		etr1_reg {
			qcom,dump-size = <0x1000>;
			qcom,dump-id = <0x105>;
		};

		misc_data {
			qcom,dump-size = <0x1000>;
			qcom,dump-id = <0xe8>;
		};

		etf_lpass {
			qcom,dump-size = <0x4000>;
			qcom,dump-id = <0xf4>;
		};

		etflpass_reg {
			qcom,dump-size = <0x1000>;
			qcom,dump-id = <0x104>;
		};

		osm_reg {
			qcom,dump-size = <0x400>;
			qcom,dump-id = <0x163>;
		};

		pcu_reg {
			qcom,dump-size = <0x400>;
			qcom,dump-id = <0x164>;
		};

		fsm_data {
			qcom,dump-size = <0x400>;
			qcom,dump-id = <0x165>;
		};
	};
};
